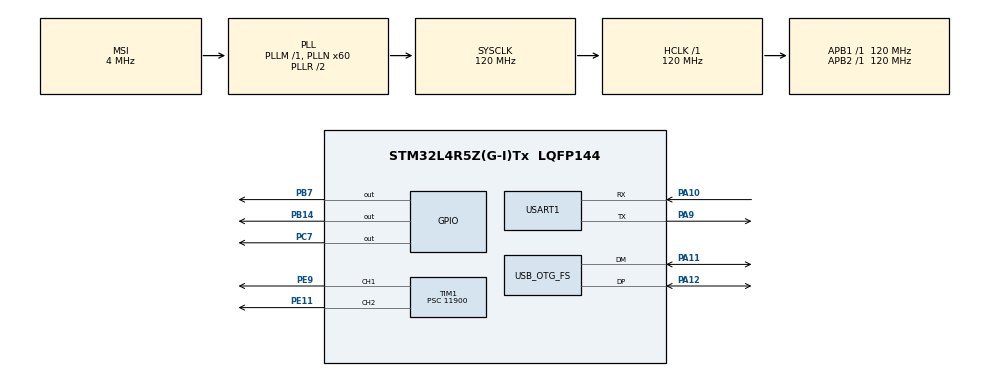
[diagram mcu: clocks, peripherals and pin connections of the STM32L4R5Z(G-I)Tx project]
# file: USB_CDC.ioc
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Mcu.Family=STM32L4
Mcu.Name=STM32L4R5Z(G-I)Tx
Mcu.Package=LQFP144
NVIC.OTG_FS_IRQn=true\:0\:0\:false\:false\:true\:false\:true
NVIC.PriorityGroup=NVIC_PRIORITYGROUP_4
NVIC.USART1_IRQn=true\:0\:0\:false\:false\:true\:true\:true
PA10.Mode=Asynchronous
PA10.Signal=USART1_RX
PA11.Mode=Device_Only
PA11.Signal=USB_OTG_FS_DM
PA12.Mode=Device_Only
PA12.Signal=USB_OTG_FS_DP
PA9.Mode=Asynchronous
PA9.Signal=USART1_TX
PB14.GPIO_ModeDefaultOutputPP=GPIO_MODE_OUTPUT_PP
PB14.GPIO_PuPd=GPIO_NOPULL
PB14.GPIO_Speed=GPIO_SPEED_FREQ_HIGH
PB14.PinState=GPIO_PIN_RESET
PB14.Signal=GPIO_Output
PB7.GPIO_FM7=__NULL
PB7.GPIO_Speed=GPIO_SPEED_FREQ_HIGH
PB7.Signal=GPIO_Output
PC7.Signal=GPIO_Output
PE11.Signal=S_TIM1_CH2
PE9.Signal=S_TIM1_CH1
PH0-OSC_IN\ (PH0).Mode=HSE-External-Oscillator
PH0-OSC_IN\ (PH0).Signal=RCC_OSC_IN
PH1-OSC_OUT\ (PH1).Mode=HSE-External-Oscillator
PH1-OSC_OUT\ (PH1).Signal=RCC_OSC_OUT
ProjectManager.HeapSize=0x200
ProjectManager.StackSize=0x400
ProjectManager.TargetToolchain=SW4STM32
RCC.ADCFreq_Value=48000000
RCC.AHBFreq_Value=120000000
RCC.APB1Freq_Value=120000000
RCC.APB1TimFreq_Value=120000000
RCC.APB2Freq_Value=120000000
RCC.APB2TimFreq_Value=120000000
RCC.CortexFreq_Value=120000000
RCC.HCLKFreq_Value=120000000
RCC.HSE_VALUE=8000000
RCC.HSI48_VALUE=48000000
RCC.HSI_VALUE=16000000
RCC.LSE_VALUE=32768
RCC.MSI_VALUE=4000000
RCC.PLLN=60
RCC.PLLSAI1N=24
RCC.SYSCLKFreq_VALUE=120000000
RCC.SYSCLKSource=RCC_SYSCLKSOURCE_PLLCLK
RCC.USBFreq_Value=48000000
RCC.VCOOutputFreq_Value=240000000
SH.S_TIM1_CH1.0=TIM1_CH1,PWM Generation1 CH1
SH.S_TIM1_CH2.0=TIM1_CH2,PWM Generation2 CH2
TIM1.Channel-PWM\ Generation1\ CH1=TIM_CHANNEL_1
TIM1.Channel-PWM\ Generation2\ CH2=TIM_CHANNEL_2
TIM1.Period=100
TIM1.Prescaler=11900
USART1.VirtualMode-Asynchronous=VM_ASYNC
USB_DEVICE.CLASS_NAME_FS=CDC
USB_DEVICE.MANUFACTURER_STRING=DHBK
USB_DEVICE.PID_CDC_FS=2020
USB_DEVICE.VID=1999
USB_DEVICE.VirtualMode=Cdc
USB_DEVICE.VirtualModeFS=Cdc_FS
USB_OTG_FS.VirtualMode=Device_Only
VP_USB_DEVICE_VS_USB_DEVICE_CDC_FS.Mode=CDC_FS
board=custom

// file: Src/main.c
/* USER CODE BEGIN Header */
/**
  ******************************************************************************
  * @file           : main.c
  * @brief          : Main program body
  ******************************************************************************
  * @attention
  *
  * <h2><center>&copy; Copyright (c) 2020 STMicroelectronics.
  * All rights reserved.</center></h2>
  *
  * This software component is licensed by ST under Ultimate Liberty license
  * SLA0044, the "License"; You may not use this file except in compliance with
  * the License. You may obtain a copy of the License at:
  *                             www.st.com/SLA0044
  *
  ******************************************************************************
  */
/* USER CODE END Header */

#include "main.h"
#include "tim.h"
#include "usart.h"
#include "usb_device.h"
#include "gpio.h"

/* USER CODE BEGIN Includes */
#include "usbd_cdc_if.h"
char receiver_data[64] = {0};
char *buff = "Hello world!!!\n";
/* USER CODE END Includes */

void SystemClock_Config(void);

int main(void)
{

  /* MCU Configuration--------------------------------------------------------*/

  /* Reset of all peripherals, Initializes the Flash interface and the Systick. */
  HAL_Init();

  /* Configure the system clock */
  SystemClock_Config();

  /* Initialize all configured peripherals */
  MX_GPIO_Init();
  MX_USB_DEVICE_Init();
  MX_TIM1_Init();
  MX_USART1_UART_Init();
  /* USER CODE BEGIN 2 */
  HAL_TIM_PWM_Start(&htim1,TIM_CHANNEL_1);
  HAL_TIM_PWM_Start(&htim1,TIM_CHANNEL_2);
  /* USER CODE END 2 */

  /* Infinite loop */
  /* USER CODE BEGIN WHILE */
  while (1)
  {
	 // HAL_GPIO_TogglePin(GPIOB,GPIO_PIN_7|GPIO_PIN_14);
	 // HAL_GPIO_TogglePin(GPIOC,GPIO_PIN_7);
	 // HAL_Delay(1000);
	  CDC_Transmit_FS((uint8_t*)buff,strlen(buff));

	  HAL_Delay(1000);
    /* USER CODE END WHILE */

  }
}

void SystemClock_Config(void)
{
  RCC_OscInitTypeDef RCC_OscInitStruct = {0};
  RCC_ClkInitTypeDef RCC_ClkInitStruct = {0};
  RCC_PeriphCLKInitTypeDef PeriphClkInit = {0};

  /** Configure the main internal regulator output voltage
  */
  if (HAL_PWREx_ControlVoltageScaling(PWR_REGULATOR_VOLTAGE_SCALE1_BOOST) != HAL_OK)
  {
    Error_Handler();
  }
  /** Initializes the CPU, AHB and APB busses clocks
  */
  RCC_OscInitStruct.OscillatorType = RCC_OSCILLATORTYPE_MSI;
  RCC_OscInitStruct.MSIState = RCC_MSI_ON;
  RCC_OscInitStruct.MSICalibrationValue = 0;
  RCC_OscInitStruct.MSIClockRange = RCC_MSIRANGE_6;
  RCC_OscInitStruct.PLL.PLLState = RCC_PLL_ON;
  RCC_OscInitStruct.PLL.PLLSource = RCC_PLLSOURCE_MSI;
  RCC_OscInitStruct.PLL.PLLM = 1;
  RCC_OscInitStruct.PLL.PLLN = 60;
  RCC_OscInitStruct.PLL.PLLP = RCC_PLLP_DIV2;
  RCC_OscInitStruct.PLL.PLLQ = RCC_PLLQ_DIV2;
  RCC_OscInitStruct.PLL.PLLR = RCC_PLLR_DIV2;
  if (HAL_RCC_OscConfig(&RCC_OscInitStruct) != HAL_OK)
  {
    Error_Handler();
  }
  /** Initializes the CPU, AHB and APB busses clocks
  */
  RCC_ClkInitStruct.ClockType = RCC_CLOCKTYPE_HCLK|RCC_CLOCKTYPE_SYSCLK
                              |RCC_CLOCKTYPE_PCLK1|RCC_CLOCKTYPE_PCLK2;
  RCC_ClkInitStruct.SYSCLKSource = RCC_SYSCLKSOURCE_PLLCLK;
  RCC_ClkInitStruct.AHBCLKDivider = RCC_SYSCLK_DIV1;
  RCC_ClkInitStruct.APB1CLKDivider = RCC_HCLK_DIV1;
  RCC_ClkInitStruct.APB2CLKDivider = RCC_HCLK_DIV1;

  if (HAL_RCC_ClockConfig(&RCC_ClkInitStruct, FLASH_LATENCY_5) != HAL_OK)
  {
    Error_Handler();
  }
  PeriphClkInit.PeriphClockSelection = RCC_PERIPHCLK_USART1|RCC_PERIPHCLK_USB;
  PeriphClkInit.Usart1ClockSelection = RCC_USART1CLKSOURCE_PCLK2;
  PeriphClkInit.UsbClockSelection = RCC_USBCLKSOURCE_PLLSAI1;
  PeriphClkInit.PLLSAI1.PLLSAI1Source = RCC_PLLSOURCE_MSI;
  PeriphClkInit.PLLSAI1.PLLSAI1M = 1;
  PeriphClkInit.PLLSAI1.PLLSAI1N = 24;
  PeriphClkInit.PLLSAI1.PLLSAI1P = RCC_PLLP_DIV2;
  PeriphClkInit.PLLSAI1.PLLSAI1Q = RCC_PLLQ_DIV2;
  PeriphClkInit.PLLSAI1.PLLSAI1R = RCC_PLLR_DIV2;
  PeriphClkInit.PLLSAI1.PLLSAI1ClockOut = RCC_PLLSAI1_48M2CLK;
  if (HAL_RCCEx_PeriphCLKConfig(&PeriphClkInit) != HAL_OK)
  {
    Error_Handler();
  }
  /** Enable MSI Auto calibration
  */
  HAL_RCCEx_EnableMSIPLLMode();
}

void Error_Handler(void)
{
}

/************************ (C) COPYRIGHT STMicroelectronics *****END OF FILE****/
